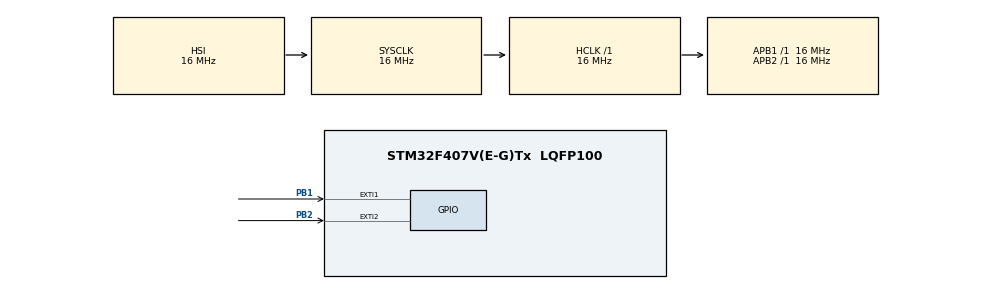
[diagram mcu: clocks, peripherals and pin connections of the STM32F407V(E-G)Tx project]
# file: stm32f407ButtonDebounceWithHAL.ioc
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Mcu.Family=STM32F4
Mcu.Name=STM32F407V(E-G)Tx
Mcu.Package=LQFP100
NVIC.EXTI1_IRQn=true\:0\:0\:false\:false\:true\:true\:true\:true
NVIC.EXTI2_IRQn=true\:0\:0\:false\:false\:true\:true\:true\:true
NVIC.PriorityGroup=NVIC_PRIORITYGROUP_4
PB1.Signal=GPXTI1
PB2.Signal=GPXTI2
ProjectManager.HeapSize=0x200
ProjectManager.StackSize=0x400
ProjectManager.TargetToolchain=STM32CubeIDE
RCC.AHBFreq_Value=16000000
RCC.APB1Freq_Value=16000000
RCC.APB2Freq_Value=16000000
RCC.CortexFreq_Value=16000000
RCC.HSE_VALUE=25000000
RCC.HSI_VALUE=16000000
RCC.LSE_VALUE=32768
RCC.SYSCLKFreq_VALUE=16000000
RCC.VCOOutputFreq_Value=192000000
board=custom

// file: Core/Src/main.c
/* USER CODE BEGIN Header */
/**
  ******************************************************************************
  * @file           : main.c
  * @brief          : Main program body
  ******************************************************************************
  * @attention
  *
  * Copyright (c) 2023 STMicroelectronics.
  * All rights reserved.
  *
  * This software is licensed under terms that can be found in the LICENSE file
  * in the root directory of this software component.
  * If no LICENSE file comes with this software, it is provided AS-IS.
  *
  ******************************************************************************
  */
/* USER CODE END Header */
#include "main.h"

/* USER CODE BEGIN PD */
#define BUTTON_REALEASED 	0
#define BUTTON_PUSHED 		1

/* USER CODE END PD */

/* USER CODE BEGIN PV */

uint8_t button1PressFlag=BUTTON_REALEASED;
uint8_t button2PressFlag=BUTTON_REALEASED;

uint8_t button1Data=BUTTON_REALEASED;
uint8_t button2Data=BUTTON_REALEASED;

uint16_t button1PressCounter=0;
uint16_t button2PressCounter=0;
uint16_t debounceTime=100;

/* USER CODE END PV */

void SystemClock_Config(void);
static void MX_GPIO_Init(void);

int main(void)
{

  /* MCU Configuration--------------------------------------------------------*/

  /* Reset of all peripherals, Initializes the Flash interface and the Systick. */
  HAL_Init();

  /* Configure the system clock */
  SystemClock_Config();

  /* Initialize all configured peripherals */
  MX_GPIO_Init();
  /* USER CODE BEGIN 2 */
  SysTick_Config(16000000/1000); //Systick timer'in ms olarak ayarlanması
  /* USER CODE END 2 */

  /* Infinite loop */
  while (1)
  {

  }
}

void SystemClock_Config(void)
{
  RCC_OscInitTypeDef RCC_OscInitStruct = {0};
  RCC_ClkInitTypeDef RCC_ClkInitStruct = {0};

  /** Configure the main internal regulator output voltage
  */
  __HAL_RCC_PWR_CLK_ENABLE();
  __HAL_PWR_VOLTAGESCALING_CONFIG(PWR_REGULATOR_VOLTAGE_SCALE1);

  /** Initializes the RCC Oscillators according to the specified parameters
  * in the RCC_OscInitTypeDef structure.
  */
  RCC_OscInitStruct.OscillatorType = RCC_OSCILLATORTYPE_HSI;
  RCC_OscInitStruct.HSIState = RCC_HSI_ON;
  RCC_OscInitStruct.HSICalibrationValue = RCC_HSICALIBRATION_DEFAULT;
  RCC_OscInitStruct.PLL.PLLState = RCC_PLL_NONE;
  if (HAL_RCC_OscConfig(&RCC_OscInitStruct) != HAL_OK)
  {
    Error_Handler();
  }

  /** Initializes the CPU, AHB and APB buses clocks
  */
  RCC_ClkInitStruct.ClockType = RCC_CLOCKTYPE_HCLK|RCC_CLOCKTYPE_SYSCLK
                              |RCC_CLOCKTYPE_PCLK1|RCC_CLOCKTYPE_PCLK2;
  RCC_ClkInitStruct.SYSCLKSource = RCC_SYSCLKSOURCE_HSI;
  RCC_ClkInitStruct.AHBCLKDivider = RCC_SYSCLK_DIV1;
  RCC_ClkInitStruct.APB1CLKDivider = RCC_HCLK_DIV1;
  RCC_ClkInitStruct.APB2CLKDivider = RCC_HCLK_DIV1;

  if (HAL_RCC_ClockConfig(&RCC_ClkInitStruct, FLASH_LATENCY_0) != HAL_OK)
  {
    Error_Handler();
  }
}

static void MX_GPIO_Init(void)
{
  GPIO_InitTypeDef GPIO_InitStruct = {0};

  /* GPIO Ports Clock Enable */
  __HAL_RCC_GPIOB_CLK_ENABLE();

  /*Configure GPIO pins : PB1 PB2 */
  GPIO_InitStruct.Pin = GPIO_PIN_1|GPIO_PIN_2;
  GPIO_InitStruct.Mode = GPIO_MODE_IT_RISING;
  GPIO_InitStruct.Pull = GPIO_NOPULL;
  HAL_GPIO_Init(GPIOB, &GPIO_InitStruct);

  /* EXTI interrupt init*/
  HAL_NVIC_SetPriority(EXTI1_IRQn, 0, 0);
  HAL_NVIC_EnableIRQ(EXTI1_IRQn);

  HAL_NVIC_SetPriority(EXTI2_IRQn, 0, 0);
  HAL_NVIC_EnableIRQ(EXTI2_IRQn);

}

/* USER CODE BEGIN 4 */

//Kodu test etmek isterseniz stm32f4xx_it.c dosyasındaki "EXTI1_IRQHandler" isimli fonksiyonu silmeniz veya commente almanız gerekmekte.
void EXTI1_IRQHandler(void){ //PB1 pinine bağlı buton için interrupt
	button1PressFlag=BUTTON_PUSHED;
	HAL_GPIO_EXTI_IRQHandler(GPIO_PIN_1);
}

//Kodu test etmek isterseniz stm32f4xx_it.c dosyasındaki "EXTI2_IRQHandler" isimli fonksiyonu silmeniz veya commente almanız gerekmekte.
void EXTI2_IRQHandler(void){//PB2 pinine bağlı buton için interrupt
	button2PressFlag=BUTTON_PUSHED;
	HAL_GPIO_EXTI_IRQHandler(GPIO_PIN_2);
}

//Kodu test etmek isterseniz stm32f4xx_it.c dosyasındaki "SysTick_Handler" isimli fonksiyonu silmeniz veya commente almanız gerekmekte.
void SysTick_Handler(void){
	HAL_IncTick();

	//PB1 pinine bağlı buton için debounce kontrolü
	if(button1PressFlag==BUTTON_PUSHED){
		if(button1PressCounter<debounceTime){
			button1PressCounter++;
		}
		else{
			if(HAL_GPIO_ReadPin(GPIOB, GPIO_PIN_1)){
				button1Data=BUTTON_PUSHED;
			}
			else{
				button1Data=BUTTON_REALEASED;

			}
			button1PressCounter=0;
			button1PressFlag=BUTTON_REALEASED;
		}
	}

	//PB2 pinine bağlı buton için debounce kontrolü
	if(button2PressFlag==BUTTON_PUSHED){
			if(button2PressCounter<debounceTime){
				button2PressCounter++;
			}
			else{
				if(HAL_GPIO_ReadPin(GPIOB, GPIO_PIN_2)){
					button2Data=BUTTON_PUSHED;
				}
				else{
					button2Data=BUTTON_REALEASED;

				}
				button2PressCounter=0;
				button2PressFlag=BUTTON_REALEASED;
			}
		}

}

/* USER CODE END 4 */

void Error_Handler(void)
{
  __disable_irq();
  while (1)
  {
  }
}
